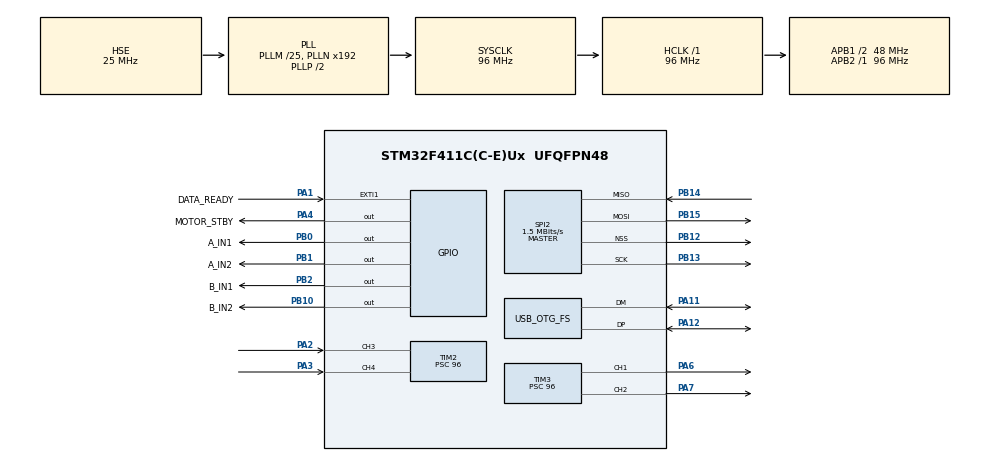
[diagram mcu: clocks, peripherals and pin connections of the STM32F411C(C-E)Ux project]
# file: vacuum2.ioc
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FREERTOS.Tasks01=defaultTask,24,512,StartDefaultTask,Default,NULL,Static,defaultTaskBuffer,defaultTaskControlBlock
FREERTOS.configENABLE_FPU=0
Mcu.Family=STM32F4
Mcu.Name=STM32F411C(C-E)Ux
Mcu.Package=UFQFPN48
NVIC.EXTI1_IRQn=true\:7\:0\:true\:false\:true\:true\:true\:true\:true
NVIC.OTG_FS_IRQn=true\:7\:0\:true\:false\:true\:true\:true\:true\:true
NVIC.PriorityGroup=NVIC_PRIORITYGROUP_4
NVIC.TIM1_TRG_COM_TIM11_IRQn=true\:15\:0\:false\:false\:true\:false\:false\:true\:true
NVIC.TimeBase=TIM1_TRG_COM_TIM11_IRQn
NVIC.TimeBaseIP=TIM11
PA1.GPIO_Label=DATA_READY
PA1.GPIO_PuPd=GPIO_PULLDOWN
PA1.Signal=GPXTI1
PA11.Mode=Device_Only
PA11.Signal=USB_OTG_FS_DM
PA12.Mode=Device_Only
PA12.Signal=USB_OTG_FS_DP
PA13.Mode=Serial_Wire
PA13.Signal=SYS_JTMS-SWDIO
PA14.Mode=Serial_Wire
PA14.Signal=SYS_JTCK-SWCLK
PA2.Signal=S_TIM2_CH3
PA3.Signal=S_TIM2_CH4
PA4.GPIO_Label=MOTOR_STBY
PA4.PinState=GPIO_PIN_SET
PA4.Signal=GPIO_Output
PA6.Signal=S_TIM3_CH1
PA7.Signal=S_TIM3_CH2
PB0.GPIO_Label=A_IN1
PB0.PinState=GPIO_PIN_SET
PB0.Signal=GPIO_Output
PB1.GPIO_Label=A_IN2
PB1.Signal=GPIO_Output
PB10.GPIO_Label=B_IN2
PB10.Signal=GPIO_Output
PB12.Mode=NSS_Signal_Hard_Output
PB12.Signal=SPI2_NSS
PB13.Mode=Full_Duplex_Master
PB13.Signal=SPI2_SCK
PB14.Mode=Full_Duplex_Master
PB14.Signal=SPI2_MISO
PB15.Mode=Full_Duplex_Master
PB15.Signal=SPI2_MOSI
PB2.GPIO_Label=B_IN1
PB2.PinState=GPIO_PIN_SET
PB2.Signal=GPIO_Output
PC14-OSC32_IN.Mode=LSE-External-Oscillator
PC14-OSC32_IN.Signal=RCC_OSC32_IN
PC15-OSC32_OUT.Mode=LSE-External-Oscillator
PC15-OSC32_OUT.Signal=RCC_OSC32_OUT
PH0\ -\ OSC_IN.Mode=HSE-External-Oscillator
PH0\ -\ OSC_IN.Signal=RCC_OSC_IN
PH1\ -\ OSC_OUT.Mode=HSE-External-Oscillator
PH1\ -\ OSC_OUT.Signal=RCC_OSC_OUT
ProjectManager.HeapSize=0x200
ProjectManager.StackSize=0x400
ProjectManager.TargetToolchain=CMake
RCC.48MHZClocksFreq_Value=48000000
RCC.AHBFreq_Value=96000000
RCC.APB1CLKDivider=RCC_HCLK_DIV2
RCC.APB1Freq_Value=48000000
RCC.APB1TimFreq_Value=96000000
RCC.APB2Freq_Value=96000000
RCC.APB2TimFreq_Value=96000000
RCC.CortexFreq_Value=96000000
RCC.HCLKFreq_Value=96000000
RCC.HSE_VALUE=25000000
RCC.HSI_VALUE=16000000
RCC.PLLM=25
RCC.SYSCLKFreq_VALUE=96000000
RCC.SYSCLKSource=RCC_SYSCLKSOURCE_PLLCLK
RCC.VCOOutputFreq_Value=192000000
SH.S_TIM2_CH3.0=TIM2_CH3,Input_Capture3_from_TI3
SH.S_TIM2_CH4.0=TIM2_CH4,Input_Capture4_from_TI4
SH.S_TIM3_CH1.0=TIM3_CH1,PWM Generation1 CH1
SH.S_TIM3_CH2.0=TIM3_CH2,PWM Generation2 CH2
SPI2.BaudRatePrescaler=SPI_BAUDRATEPRESCALER_32
SPI2.CalculateBaudRate=1.5 MBits/s
SPI2.Direction=SPI_DIRECTION_2LINES
SPI2.Mode=SPI_MODE_MASTER
SPI2.VirtualNSS=VM_NSSHARD
SPI2.VirtualType=VM_MASTER
TIM2.Channel-Input_Capture3_from_TI3=TIM_CHANNEL_3
TIM2.Channel-Input_Capture4_from_TI4=TIM_CHANNEL_4
TIM2.ICFilter_CH3=15
TIM2.ICFilter_CH4=15
TIM2.Prescaler=96
TIM3.Channel-PWM\ Generation1\ CH1=TIM_CHANNEL_1
TIM3.Channel-PWM\ Generation2\ CH2=TIM_CHANNEL_2
TIM3.Period=100
TIM3.Prescaler=96
TIM3.Pulse-PWM\ Generation1\ CH1=50
TIM3.Pulse-PWM\ Generation2\ CH2=50
USB_DEVICE.CLASS_NAME_FS=CDC
USB_DEVICE.VirtualMode=Cdc
USB_DEVICE.VirtualModeFS=Cdc_FS
USB_OTG_FS.VirtualMode=Device_Only
VP_FREERTOS_VS_CMSIS_V2.Mode=CMSIS_V2
VP_SYS_VS_tim11.Mode=TIM11
VP_TIM2_VS_ClockSourceINT.Mode=Internal
VP_TIM3_VS_ClockSourceINT.Mode=Internal
VP_USB_DEVICE_VS_USB_DEVICE_CDC_FS.Mode=CDC_FS
board=custom

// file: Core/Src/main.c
/* USER CODE BEGIN Header */
/**
  ******************************************************************************
  * @file           : main.c
  * @brief          : Main program body
  ******************************************************************************
  * @attention
  *
  * Copyright (c) 2025 STMicroelectronics.
  * All rights reserved.
  *
  * This software is licensed under terms that can be found in the LICENSE file
  * in the root directory of this software component.
  * If no LICENSE file comes with this software, it is provided AS-IS.
  *
  ******************************************************************************
  */
/* USER CODE END Header */
#include "main.h"
#include "cmsis_os.h"
#include "usb_device.h"

/* USER CODE BEGIN Includes */
#include "MainThread.h"
/* USER CODE END Includes */

typedef StaticTask_t osStaticThreadDef_t;

SPI_HandleTypeDef hspi2;

TIM_HandleTypeDef htim2;
TIM_HandleTypeDef htim3;

/* Definitions for defaultTask */
osThreadId_t defaultTaskHandle;
uint32_t defaultTaskBuffer[ 512 ];
osStaticThreadDef_t defaultTaskControlBlock;
const osThreadAttr_t defaultTask_attributes = {
  .name = "defaultTask",
  .cb_mem = &defaultTaskControlBlock,
  .cb_size = sizeof(defaultTaskControlBlock),
  .stack_mem = &defaultTaskBuffer[0],
  .stack_size = sizeof(defaultTaskBuffer),
  .priority = (osPriority_t) osPriorityNormal,
};

void SystemClock_Config(void);
static void MX_GPIO_Init(void);
static void MX_TIM2_Init(void);
static void MX_TIM3_Init(void);
static void MX_SPI2_Init(void);
void StartDefaultTask(void *argument);

int main(void)
{

  /* MCU Configuration--------------------------------------------------------*/

  /* Reset of all peripherals, Initializes the Flash interface and the Systick. */
  HAL_Init();

  /* Configure the system clock */
  SystemClock_Config();

  /* Initialize all configured peripherals */
  MX_GPIO_Init();
  MX_TIM2_Init();
  MX_TIM3_Init();
  MX_SPI2_Init();
  /* USER CODE BEGIN 2 */
  HAL_TIM_IC_Start_IT(&htim3, TIM_CHANNEL_1);
  HAL_TIM_IC_Start_IT(&htim3, TIM_CHANNEL_2);
  /* USER CODE END 2 */

  /* Init scheduler */
  osKernelInitialize();

  /* Create the thread(s) */
  /* creation of defaultTask */
  defaultTaskHandle = osThreadNew(StartDefaultTask, NULL, &defaultTask_attributes);

  /* Start scheduler */
  osKernelStart();

  /* We should never get here as control is now taken by the scheduler */

  /* Infinite loop */
  while (1)
  {

  }
}

void SystemClock_Config(void)
{
  RCC_OscInitTypeDef RCC_OscInitStruct = {0};
  RCC_ClkInitTypeDef RCC_ClkInitStruct = {0};

  /** Configure the main internal regulator output voltage
  */
  __HAL_RCC_PWR_CLK_ENABLE();
  __HAL_PWR_VOLTAGESCALING_CONFIG(PWR_REGULATOR_VOLTAGE_SCALE1);

  /** Initializes the RCC Oscillators according to the specified parameters
  * in the RCC_OscInitTypeDef structure.
  */
  RCC_OscInitStruct.OscillatorType = RCC_OSCILLATORTYPE_HSE;
  RCC_OscInitStruct.HSEState = RCC_HSE_ON;
  RCC_OscInitStruct.PLL.PLLState = RCC_PLL_ON;
  RCC_OscInitStruct.PLL.PLLSource = RCC_PLLSOURCE_HSE;
  RCC_OscInitStruct.PLL.PLLM = 25;
  RCC_OscInitStruct.PLL.PLLN = 192;
  RCC_OscInitStruct.PLL.PLLP = RCC_PLLP_DIV2;
  RCC_OscInitStruct.PLL.PLLQ = 4;
  if (HAL_RCC_OscConfig(&RCC_OscInitStruct) != HAL_OK)
  {
    Error_Handler();
  }

  /** Initializes the CPU, AHB and APB buses clocks
  */
  RCC_ClkInitStruct.ClockType = RCC_CLOCKTYPE_HCLK|RCC_CLOCKTYPE_SYSCLK
                              |RCC_CLOCKTYPE_PCLK1|RCC_CLOCKTYPE_PCLK2;
  RCC_ClkInitStruct.SYSCLKSource = RCC_SYSCLKSOURCE_PLLCLK;
  RCC_ClkInitStruct.AHBCLKDivider = RCC_SYSCLK_DIV1;
  RCC_ClkInitStruct.APB1CLKDivider = RCC_HCLK_DIV2;
  RCC_ClkInitStruct.APB2CLKDivider = RCC_HCLK_DIV1;

  if (HAL_RCC_ClockConfig(&RCC_ClkInitStruct, FLASH_LATENCY_3) != HAL_OK)
  {
    Error_Handler();
  }
}

static void MX_SPI2_Init(void)
{

  /* SPI2 parameter configuration*/
  hspi2.Instance = SPI2;
  hspi2.Init.Mode = SPI_MODE_MASTER;
  hspi2.Init.Direction = SPI_DIRECTION_2LINES;
  hspi2.Init.DataSize = SPI_DATASIZE_8BIT;
  hspi2.Init.CLKPolarity = SPI_POLARITY_LOW;
  hspi2.Init.CLKPhase = SPI_PHASE_1EDGE;
  hspi2.Init.NSS = SPI_NSS_HARD_OUTPUT;
  hspi2.Init.BaudRatePrescaler = SPI_BAUDRATEPRESCALER_32;
  hspi2.Init.FirstBit = SPI_FIRSTBIT_MSB;
  hspi2.Init.TIMode = SPI_TIMODE_DISABLE;
  hspi2.Init.CRCCalculation = SPI_CRCCALCULATION_DISABLE;
  hspi2.Init.CRCPolynomial = 10;
  if (HAL_SPI_Init(&hspi2) != HAL_OK)
  {
    Error_Handler();
  }

}

static void MX_TIM2_Init(void)
{

  TIM_ClockConfigTypeDef sClockSourceConfig = {0};
  TIM_MasterConfigTypeDef sMasterConfig = {0};
  TIM_IC_InitTypeDef sConfigIC = {0};

  htim2.Instance = TIM2;
  htim2.Init.Prescaler = 96;
  htim2.Init.CounterMode = TIM_COUNTERMODE_UP;
  htim2.Init.Period = 4294967295;
  htim2.Init.ClockDivision = TIM_CLOCKDIVISION_DIV1;
  htim2.Init.AutoReloadPreload = TIM_AUTORELOAD_PRELOAD_DISABLE;
  if (HAL_TIM_Base_Init(&htim2) != HAL_OK)
  {
    Error_Handler();
  }
  sClockSourceConfig.ClockSource = TIM_CLOCKSOURCE_INTERNAL;
  if (HAL_TIM_ConfigClockSource(&htim2, &sClockSourceConfig) != HAL_OK)
  {
    Error_Handler();
  }
  if (HAL_TIM_IC_Init(&htim2) != HAL_OK)
  {
    Error_Handler();
  }
  sMasterConfig.MasterOutputTrigger = TIM_TRGO_RESET;
  sMasterConfig.MasterSlaveMode = TIM_MASTERSLAVEMODE_DISABLE;
  if (HAL_TIMEx_MasterConfigSynchronization(&htim2, &sMasterConfig) != HAL_OK)
  {
    Error_Handler();
  }
  sConfigIC.ICPolarity = TIM_INPUTCHANNELPOLARITY_RISING;
  sConfigIC.ICSelection = TIM_ICSELECTION_DIRECTTI;
  sConfigIC.ICPrescaler = TIM_ICPSC_DIV1;
  sConfigIC.ICFilter = 15;
  if (HAL_TIM_IC_ConfigChannel(&htim2, &sConfigIC, TIM_CHANNEL_3) != HAL_OK)
  {
    Error_Handler();
  }
  if (HAL_TIM_IC_ConfigChannel(&htim2, &sConfigIC, TIM_CHANNEL_4) != HAL_OK)
  {
    Error_Handler();
  }

}

static void MX_TIM3_Init(void)
{

  TIM_ClockConfigTypeDef sClockSourceConfig = {0};
  TIM_MasterConfigTypeDef sMasterConfig = {0};
  TIM_OC_InitTypeDef sConfigOC = {0};

  htim3.Instance = TIM3;
  htim3.Init.Prescaler = 96;
  htim3.Init.CounterMode = TIM_COUNTERMODE_UP;
  htim3.Init.Period = 100;
  htim3.Init.ClockDivision = TIM_CLOCKDIVISION_DIV1;
  htim3.Init.AutoReloadPreload = TIM_AUTORELOAD_PRELOAD_DISABLE;
  if (HAL_TIM_Base_Init(&htim3) != HAL_OK)
  {
    Error_Handler();
  }
  sClockSourceConfig.ClockSource = TIM_CLOCKSOURCE_INTERNAL;
  if (HAL_TIM_ConfigClockSource(&htim3, &sClockSourceConfig) != HAL_OK)
  {
    Error_Handler();
  }
  if (HAL_TIM_PWM_Init(&htim3) != HAL_OK)
  {
    Error_Handler();
  }
  sMasterConfig.MasterOutputTrigger = TIM_TRGO_RESET;
  sMasterConfig.MasterSlaveMode = TIM_MASTERSLAVEMODE_DISABLE;
  if (HAL_TIMEx_MasterConfigSynchronization(&htim3, &sMasterConfig) != HAL_OK)
  {
    Error_Handler();
  }
  sConfigOC.OCMode = TIM_OCMODE_PWM1;
  sConfigOC.Pulse = 50;
  sConfigOC.OCPolarity = TIM_OCPOLARITY_HIGH;
  sConfigOC.OCFastMode = TIM_OCFAST_DISABLE;
  if (HAL_TIM_PWM_ConfigChannel(&htim3, &sConfigOC, TIM_CHANNEL_1) != HAL_OK)
  {
    Error_Handler();
  }
  if (HAL_TIM_PWM_ConfigChannel(&htim3, &sConfigOC, TIM_CHANNEL_2) != HAL_OK)
  {
    Error_Handler();
  }
  HAL_TIM_MspPostInit(&htim3);

}

static void MX_GPIO_Init(void)
{
  GPIO_InitTypeDef GPIO_InitStruct = {0};

  /* GPIO Ports Clock Enable */
  __HAL_RCC_GPIOC_CLK_ENABLE();
  __HAL_RCC_GPIOH_CLK_ENABLE();
  __HAL_RCC_GPIOA_CLK_ENABLE();
  __HAL_RCC_GPIOB_CLK_ENABLE();

  /*Configure GPIO pin Output Level */
  HAL_GPIO_WritePin(MOTOR_STBY_GPIO_Port, MOTOR_STBY_Pin, GPIO_PIN_SET);

  /*Configure GPIO pin Output Level */
  HAL_GPIO_WritePin(GPIOB, A_IN1_Pin|B_IN1_Pin, GPIO_PIN_SET);

  /*Configure GPIO pin Output Level */
  HAL_GPIO_WritePin(GPIOB, A_IN2_Pin|B_IN2_Pin, GPIO_PIN_RESET);

  /*Configure GPIO pin : DATA_READY_Pin */
  GPIO_InitStruct.Pin = DATA_READY_Pin;
  GPIO_InitStruct.Mode = GPIO_MODE_IT_RISING;
  GPIO_InitStruct.Pull = GPIO_PULLDOWN;
  HAL_GPIO_Init(DATA_READY_GPIO_Port, &GPIO_InitStruct);

  /*Configure GPIO pin : MOTOR_STBY_Pin */
  GPIO_InitStruct.Pin = MOTOR_STBY_Pin;
  GPIO_InitStruct.Mode = GPIO_MODE_OUTPUT_PP;
  GPIO_InitStruct.Pull = GPIO_NOPULL;
  GPIO_InitStruct.Speed = GPIO_SPEED_FREQ_LOW;
  HAL_GPIO_Init(MOTOR_STBY_GPIO_Port, &GPIO_InitStruct);

  /*Configure GPIO pins : A_IN1_Pin A_IN2_Pin B_IN1_Pin B_IN2_Pin */
  GPIO_InitStruct.Pin = A_IN1_Pin|A_IN2_Pin|B_IN1_Pin|B_IN2_Pin;
  GPIO_InitStruct.Mode = GPIO_MODE_OUTPUT_PP;
  GPIO_InitStruct.Pull = GPIO_NOPULL;
  GPIO_InitStruct.Speed = GPIO_SPEED_FREQ_LOW;
  HAL_GPIO_Init(GPIOB, &GPIO_InitStruct);

  /* EXTI interrupt init*/
  HAL_NVIC_SetPriority(EXTI1_IRQn, 7, 0);
  HAL_NVIC_EnableIRQ(EXTI1_IRQn);

}

void StartDefaultTask(void *argument)
{
  /* init code for USB_DEVICE */
  MX_USB_DEVICE_Init();
  /* USER CODE BEGIN 5 */

  mainThread();
  /* USER CODE END 5 */
}

void HAL_TIM_PeriodElapsedCallback(TIM_HandleTypeDef *htim)
{
  if (htim->Instance == TIM11)
  {
    HAL_IncTick();
  }
}

void Error_Handler(void)
{
  __disable_irq();
  while (1)
  {
  }
}
